# STM32F413 register map
File version: 1.9
CPU: CM4 r0p1, little endian, MPU, FPU, 4 interrupt priority bits
Registers are 32-bit, read-write, reset 0x0 unless marked. A register's access mark holds for its fields unless they carry their own. Offsets are from the block's base; [hi:lo] are bit positions.

## UART4 — Universal synchronous asynchronous receiver transmitter
Base 0x40004C00
Same registers: UART5 0x40005000, UART7 0x40007800, UART8 0x40007C00, UART9 0x40011800, UART10 0x40011C00
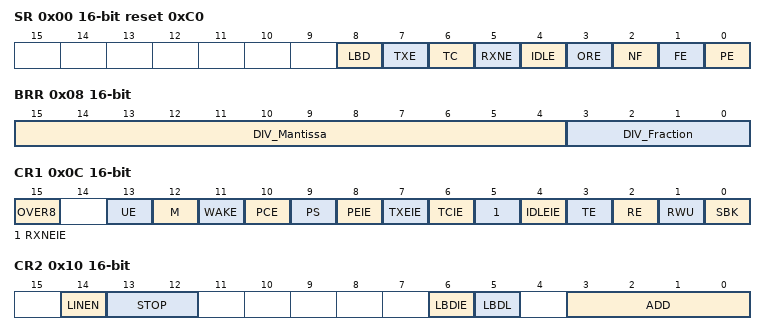
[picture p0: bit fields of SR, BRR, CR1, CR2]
0x00 SR 16-bit access per field reset 0xC0 — Status register
  [8] LBD rw write-0-clears — LIN break detection flag
    on read: 0=NotDetected (LIN break not detected); 1=Detected (LIN break detected) | on write: 0=Clear LIN break detection flag
  [7] TXE ro — Transmit data register empty
    0=TxNotEmpty (Data is not transferred to the shift register); 1=TxEmpty (Data is transferred to the shift register)
  [6] TC rw write-0-clears — Transmission complete
    on read: 0=TxNotComplete (Transmission is not complete); 1=TxComplete (Transmission is complete) | on write: 0=Clear transmission complete flag
  [5] RXNE rw write-0-clears — Read data register not empty
    on read: 0=NoData (Data is not received); 1=DataReady (Received data is ready to be read) | on write: 0=Clear received data ready flag
  [4] IDLE ro — IDLE line detected
    0=No Idle Line is detected; 1=Idle Line is detected
  [3] ORE ro — Overrun error
    0=No Overrun error; 1=Overrun error is detected
  [2] NF ro — Noise detected flag
    0=No noise is detected; 1=Noise is detected
  [1] FE ro — Framing error
    0=NoError (No Framing error is detected); 1=Error (Framing error or break character is detected)
  [0] PE ro — Parity error
    0=NoError (No parity error); 1=Error (Parity error)
0x04 DR 16-bit — Data register
  [8:0] DR — Data value
0x08 BRR 16-bit — Baud rate register
  [15:4] DIV_Mantissa — mantissa of USARTDIV
  [3:0] DIV_Fraction — fraction of USARTDIV
0x0C CR1 16-bit — Control register 1
  [15] OVER8 — Oversampling mode
    0=Oversample16 (Oversampling by 16); 1=Oversample8 (Oversampling by 8)
  [13] UE — USART enable
    0=Disabled (USART prescaler and outputs disabled); 1=Enabled (USART enabled)
  [12] M — Word length
    0=8 data bits; 1=9 data bits
  [11] WAKE — Wakeup method
    0=IdleLine (USART wakeup on idle line); 1=AddressMark (USART wakeup on address mark)
  [10] PCE — Parity control enable
    0=Disabled (Parity control disabled); 1=Enabled (Parity control enabled)
  [9] PS — Parity selection
    0=Even parity; 1=Odd (Odd parity)
  [8] PEIE — PE interrupt enable
    0=Disabled (PE interrupt disabled); 1=Enabled (PE interrupt enabled)
  [7] TXEIE — TXE interrupt enable
    0=Disabled (TXE interrupt disabled); 1=Enabled (TXE interrupt enabled)
  [6] TCIE — Transmission complete interrupt enable
    0=Disabled (TC interrupt disabled); 1=Enabled (TC interrupt enabled)
  [5] RXNEIE — RXNE interrupt enable
    0=Disabled (RXNE interrupt disabled); 1=Enabled (RXNE interrupt enabled)
  [4] IDLEIE — IDLE interrupt enable
    0=Disabled (IDLE interrupt disabled); 1=Enabled (IDLE interrupt enabled)
  [3] TE — Transmitter enable
    0=Disabled (Transmitter disabled); 1=Enabled (Transmitter enabled)
  [2] RE — Receiver enable
    0=Disabled (Receiver disabled); 1=Enabled (Receiver enabled)
  [1] RWU — Receiver wakeup
    0=Active (Receiver in active mode); 1=Mute (Receiver in mute mode)
  [0] SBK — Send break
    0=No break character is transmitted; 1=Break character transmitted
0x10 CR2 16-bit — Control register 2
  [14] LINEN — LIN mode enable
    0=Disabled (LIN mode disabled); 1=Enabled (LIN mode enabled)
  [13:12] STOP — STOP bits
    0=1 stop bit; 2=2 stop bits
  [6] LBDIE — LIN break detection interrupt enable
    0=Disabled (LIN break detection interrupt disabled); 1=Enabled (LIN break detection interrupt enabled)
  [5] LBDL — lin break detection length
    0=10-bit break detection; 1=11-bit break detection
  [3:0] ADD — Address of the USART node
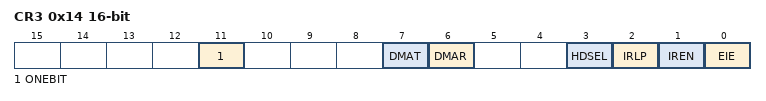
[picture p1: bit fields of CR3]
0x14 CR3 16-bit — Control register 3
  [11] ONEBIT — One sample bit method enable
    0=Sample3 (Three sample bit method); 1=Sample1 (One sample bit method)
  [7] DMAT — DMA enable transmitter
    0=Disabled (DMA mode is disabled for transmission); 1=Enabled (DMA mode is enabled for transmission)
  [6] DMAR — DMA enable receiver
    0=Disabled (DMA mode is disabled for reception); 1=Enabled (DMA mode is enabled for reception)
  [3] HDSEL — Half-duplex selection
    0=FullDuplex (Half duplex mode is not selected); 1=Half duplex mode is selected
  [2] IRLP — IrDA low-power
    0=Normal mode; 1=Low-power mode
  [1] IREN — IrDA mode enable
    0=Disabled (IrDA disabled); 1=Enabled (IrDA enabled)
  [0] EIE — Error interrupt enable
    0=Disabled (Error interrupt disabled); 1=Enabled (Error interrupt enabled)
0x18 GTPR 16-bit — Guard Time and Prescaler Register
  [7:0] PSC range 1..255 — IrDA Low-Power pulse width peripheral clock prescaler
